AUTOSAR XML (schema 314)
package /ComponentType
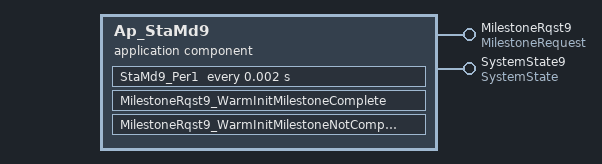
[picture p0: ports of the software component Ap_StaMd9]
  application software component type Ap_StaMd9
    provide port MilestoneRqst9: provided-interface=MilestoneRequest
      provided-com-specs:
        operation=WarmInitMilestoneComplete, queue-length=1
        operation=WarmInitMilestoneNotComplete, queue-length=1
    provide port SystemState9: mode-switch-com-spec{mode-group=Mode, queue-length=1}, provided-interface=SystemState
  internal behavior Ap_StaMd9_InternalBehavior: component=Ap_StaMd9
    operation invoked event OIT_MilestoneRqst9_WarmInitMilestoneComplete_MilestoneRqst9_WarmInitMilestoneComplete: start-on-event=MilestoneRqst9_WarmInitMilestoneComplete, operation=MilestoneRqst9.WarmInitMilestoneComplete
    operation invoked event OIT_MilestoneRqst9_WarmInitMilestoneNotComplete_MilestoneRqst9_WarmInitMilestoneNotComplete: start-on-event=MilestoneRqst9_WarmInitMilestoneNotComplete, operation=MilestoneRqst9.WarmInitMilestoneNotComplete
    timing event TMT_StaMd9_Per1: start-on-event=StaMd9_Per1, period=0.002
    exclusive area StaMds9_MilestoneRqst_WARMINIT_ExclArea
    port-api-options:
      enable-take-address=false, indirect-api=false, port=MilestoneRqst9
      enable-take-address=false, indirect-api=false, port=SystemState9
    runnable MilestoneRqst9_WarmInitMilestoneComplete: can-be-invoked-concurrently=true, can-enter-exclusive-area=StaMds9_MilestoneRqst_WARMINIT_ExclArea
    runnable MilestoneRqst9_WarmInitMilestoneNotComplete: can-be-invoked-concurrently=true, can-enter-exclusive-area=StaMds9_MilestoneRqst_WARMINIT_ExclArea
    runnable StaMd9_Per1
      mode switch point SWITCH_SystemState9_Mode: mode-group=SystemState9.Mode
  swc implementation Ap_StaMd9_Implementation: behavior=Ap_StaMd9_InternalBehavior
    code-descriptors:
      code Code: type=SRC
